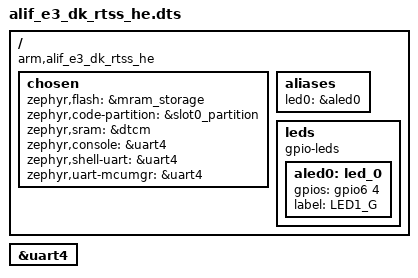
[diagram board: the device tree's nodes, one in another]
/* Copyright (c) 2024 Alif Semiconductor
 *
 * SPDX-License-Identifier: Apache-2.0
 */
/dts-v1/;

#include <alif/e3_rtss_common.dtsi>
#include <alif/ensemble_rtss_he.dtsi>
#include <alif/ensemble-pinctrl.dtsi>

/ {
	compatible = "arm,alif_e3_dk_rtss_he";
	#address-cells = <1>;
	#size-cells = <1>;

	chosen {
		zephyr,flash = &mram_storage;
		zephyr,code-partition = &slot0_partition;
		zephyr,sram = &dtcm;
		zephyr,console = &uart4;
		zephyr,shell-uart = &uart4;
		zephyr,uart-mcumgr = &uart4;
	};

	aliases {
		led0 = &aled0;
	};
	leds {
		compatible = "gpio-leds";
		aled0: led_0 {
			gpios = <&gpio6 4 0>;
			label = "LED1_G";
		};
	};
};
&uart4 {
	status = "okay";
};
